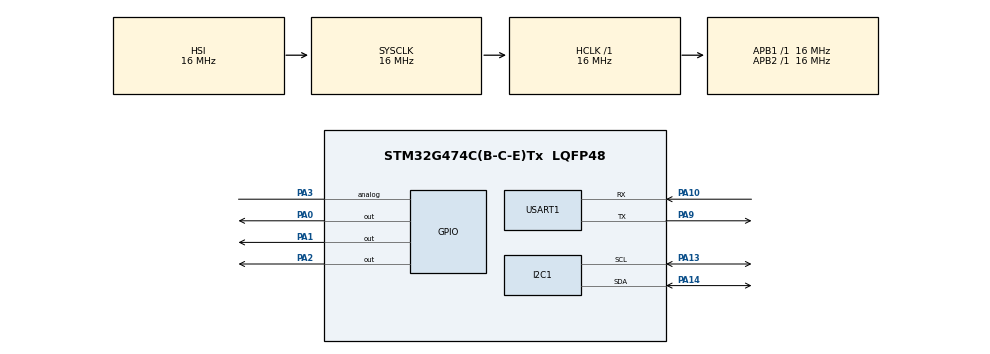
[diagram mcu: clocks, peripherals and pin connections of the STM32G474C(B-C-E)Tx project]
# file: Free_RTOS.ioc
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FREERTOS.BinarySemaphores01=myBinarySem01,Dynamic,NULL,Available
FREERTOS.Tasks01=defaultTask,-2,128,StartDefaultTask,Default,NULL,Dynamic,NULL,NULL;Task3,2,128,Task3_init,Default,NULL,Dynamic,NULL,NULL;Task2,0,128,StartTask03,Default,NULL,Dynamic,NULL,NULL;myTask04,2,128,StartTask04,Default,NULL,Dynamic,NULL,NULL
FREERTOS.configMINIMAL_STACK_SIZE=64
FREERTOS.configUSE_NEWLIB_REENTRANT=1
I2C1.Timing=0x00503D58
Mcu.Family=STM32G4
Mcu.Name=STM32G474C(B-C-E)Tx
Mcu.Package=LQFP48
NVIC.PriorityGroup=NVIC_PRIORITYGROUP_4
NVIC.TIM1_UP_TIM16_IRQn=true\:15\:0\:false\:false\:true\:false\:false\:true\:true
NVIC.TimeBase=TIM1_UP_TIM16_IRQn
NVIC.TimeBaseIP=TIM1
NVIC.USART1_IRQn=true\:5\:0\:false\:false\:true\:true\:true\:true\:true
PA0.Signal=GPIO_Output
PA1.Signal=GPIO_Output
PA10.Mode=Asynchronous
PA10.Signal=USART1_RX
PA13.Mode=I2C
PA13.Signal=I2C1_SCL
PA14.Mode=I2C
PA14.Signal=I2C1_SDA
PA2.Signal=GPIO_Output
PA3.Signal=GPIO_Analog
PA9.Mode=Asynchronous
PA9.Signal=USART1_TX
ProjectManager.HeapSize=0x200
ProjectManager.StackSize=0x400
ProjectManager.TargetToolchain=STM32CubeIDE
RCC.AHBFreq_Value=16000000
RCC.APB1Freq_Value=16000000
RCC.APB1TimFreq_Value=16000000
RCC.APB2Freq_Value=16000000
RCC.APB2TimFreq_Value=16000000
RCC.CortexFreq_Value=16000000
RCC.EXTERNAL_CLOCK_VALUE=12288000
RCC.HCLKFreq_Value=16000000
RCC.HSE_VALUE=8000000
RCC.HSI48_VALUE=48000000
RCC.HSI_VALUE=16000000
RCC.LSE_VALUE=32768
RCC.SYSCLKFreq_VALUE=16000000
RCC.USBFreq_Value=64000000
RCC.VCOOutputFreq_Value=128000000
USART1.VirtualMode-Asynchronous=VM_ASYNC
VP_FREERTOS_VS_CMSIS_V1.Mode=CMSIS_V1
VP_SYS_VS_DBSignals.Mode=DisableDeadBatterySignals
VP_SYS_VS_tim1.Mode=TIM1
board=custom

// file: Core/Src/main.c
/* USER CODE BEGIN Header */
/* USER CODE END Header */
#include "main.h"
#include "cmsis_os.h"

I2C_HandleTypeDef hi2c1;

UART_HandleTypeDef huart1;

osThreadId defaultTaskHandle;
osThreadId Task3Handle;
osThreadId Task2Handle;
osThreadId myTask04Handle;
osSemaphoreId myBinarySem01Handle;

void SystemClock_Config(void);
static void MX_GPIO_Init(void);
static void MX_USART1_UART_Init(void);
static void MX_I2C1_Init(void);
void StartDefaultTask(void const * argument);
void Task3_init(void const * argument);
void StartTask03(void const * argument);
void StartTask04(void const * argument);

int main(void)
{

  /* MCU Configuration--------------------------------------------------------*/

  /* Reset of all peripherals, Initializes the Flash interface and the Systick. */
  HAL_Init();

  /* Configure the system clock */
  SystemClock_Config();

  /* Initialize all configured peripherals */
  MX_GPIO_Init();
  MX_USART1_UART_Init();
  MX_I2C1_Init();

  /* Create the semaphores(s) */
  /* definition and creation of myBinarySem01 */
  osSemaphoreDef(myBinarySem01);
  myBinarySem01Handle = osSemaphoreCreate(osSemaphore(myBinarySem01), 1);

  /* Create the thread(s) */
  /* definition and creation of defaultTask */
  osThreadDef(defaultTask, StartDefaultTask, osPriorityLow, 0, 128);
  defaultTaskHandle = osThreadCreate(osThread(defaultTask), NULL);

  /* definition and creation of Task3 */
  osThreadDef(Task3, Task3_init, osPriorityHigh, 0, 128);
  Task3Handle = osThreadCreate(osThread(Task3), NULL);

  /* definition and creation of Task2 */
  osThreadDef(Task2, StartTask03, osPriorityNormal, 0, 128);
  Task2Handle = osThreadCreate(osThread(Task2), NULL);

  /* definition and creation of myTask04 */
  osThreadDef(myTask04, StartTask04, osPriorityHigh, 0, 128);
  myTask04Handle = osThreadCreate(osThread(myTask04), NULL);

  /* Start scheduler */
  osKernelStart();

  /* We should never get here as control is now taken by the scheduler */

  /* Infinite loop */

}

void SystemClock_Config(void)
{
  RCC_OscInitTypeDef RCC_OscInitStruct = {0};
  RCC_ClkInitTypeDef RCC_ClkInitStruct = {0};

  /** Configure the main internal regulator output voltage
  */
  HAL_PWREx_ControlVoltageScaling(PWR_REGULATOR_VOLTAGE_SCALE1);

  /** Initializes the RCC Oscillators according to the specified parameters
  * in the RCC_OscInitTypeDef structure.
  */
  RCC_OscInitStruct.OscillatorType = RCC_OSCILLATORTYPE_HSI;
  RCC_OscInitStruct.HSIState = RCC_HSI_ON;
  RCC_OscInitStruct.HSICalibrationValue = RCC_HSICALIBRATION_DEFAULT;
  RCC_OscInitStruct.PLL.PLLState = RCC_PLL_NONE;
  if (HAL_RCC_OscConfig(&RCC_OscInitStruct) != HAL_OK)
  {
    Error_Handler();
  }

  /** Initializes the CPU, AHB and APB buses clocks
  */
  RCC_ClkInitStruct.ClockType = RCC_CLOCKTYPE_HCLK|RCC_CLOCKTYPE_SYSCLK
                              |RCC_CLOCKTYPE_PCLK1|RCC_CLOCKTYPE_PCLK2;
  RCC_ClkInitStruct.SYSCLKSource = RCC_SYSCLKSOURCE_HSI;
  RCC_ClkInitStruct.AHBCLKDivider = RCC_SYSCLK_DIV1;
  RCC_ClkInitStruct.APB1CLKDivider = RCC_HCLK_DIV1;
  RCC_ClkInitStruct.APB2CLKDivider = RCC_HCLK_DIV1;

  if (HAL_RCC_ClockConfig(&RCC_ClkInitStruct, FLASH_LATENCY_0) != HAL_OK)
  {
    Error_Handler();
  }
}

static void MX_I2C1_Init(void)
{

  hi2c1.Instance = I2C1;
  hi2c1.Init.Timing = 0x00503D58;
  hi2c1.Init.OwnAddress1 = 0;
  hi2c1.Init.AddressingMode = I2C_ADDRESSINGMODE_7BIT;
  hi2c1.Init.DualAddressMode = I2C_DUALADDRESS_DISABLE;
  hi2c1.Init.OwnAddress2 = 0;
  hi2c1.Init.OwnAddress2Masks = I2C_OA2_NOMASK;
  hi2c1.Init.GeneralCallMode = I2C_GENERALCALL_DISABLE;
  hi2c1.Init.NoStretchMode = I2C_NOSTRETCH_DISABLE;
  if (HAL_I2C_Init(&hi2c1) != HAL_OK)
  {
    Error_Handler();
  }

  /** Configure Analogue filter
  */
  if (HAL_I2CEx_ConfigAnalogFilter(&hi2c1, I2C_ANALOGFILTER_ENABLE) != HAL_OK)
  {
    Error_Handler();
  }

  /** Configure Digital filter
  */
  if (HAL_I2CEx_ConfigDigitalFilter(&hi2c1, 0) != HAL_OK)
  {
    Error_Handler();
  }

}

static void MX_USART1_UART_Init(void)
{

  huart1.Instance = USART1;
  huart1.Init.BaudRate = 115200;
  huart1.Init.WordLength = UART_WORDLENGTH_8B;
  huart1.Init.StopBits = UART_STOPBITS_1;
  huart1.Init.Parity = UART_PARITY_NONE;
  huart1.Init.Mode = UART_MODE_TX_RX;
  huart1.Init.HwFlowCtl = UART_HWCONTROL_NONE;
  huart1.Init.OverSampling = UART_OVERSAMPLING_16;
  huart1.Init.OneBitSampling = UART_ONE_BIT_SAMPLE_DISABLE;
  huart1.Init.ClockPrescaler = UART_PRESCALER_DIV1;
  huart1.AdvancedInit.AdvFeatureInit = UART_ADVFEATURE_NO_INIT;
  if (HAL_UART_Init(&huart1) != HAL_OK)
  {
    Error_Handler();
  }
  if (HAL_UARTEx_SetTxFifoThreshold(&huart1, UART_TXFIFO_THRESHOLD_1_8) != HAL_OK)
  {
    Error_Handler();
  }
  if (HAL_UARTEx_SetRxFifoThreshold(&huart1, UART_RXFIFO_THRESHOLD_1_8) != HAL_OK)
  {
    Error_Handler();
  }
  if (HAL_UARTEx_DisableFifoMode(&huart1) != HAL_OK)
  {
    Error_Handler();
  }

}

static void MX_GPIO_Init(void)
{
  GPIO_InitTypeDef GPIO_InitStruct = {0};

  /* GPIO Ports Clock Enable */
  __HAL_RCC_GPIOA_CLK_ENABLE();

  /*Configure GPIO pin Output Level */
  HAL_GPIO_WritePin(GPIOA, GPIO_PIN_0|GPIO_PIN_1|GPIO_PIN_2, GPIO_PIN_RESET);

  /*Configure GPIO pins : PA0 PA1 PA2 */
  GPIO_InitStruct.Pin = GPIO_PIN_0|GPIO_PIN_1|GPIO_PIN_2;
  GPIO_InitStruct.Mode = GPIO_MODE_OUTPUT_PP;
  GPIO_InitStruct.Pull = GPIO_NOPULL;
  GPIO_InitStruct.Speed = GPIO_SPEED_FREQ_LOW;
  HAL_GPIO_Init(GPIOA, &GPIO_InitStruct);

  /*Configure GPIO pin : PA3 */
  GPIO_InitStruct.Pin = GPIO_PIN_3;
  GPIO_InitStruct.Mode = GPIO_MODE_ANALOG;
  GPIO_InitStruct.Pull = GPIO_NOPULL;
  HAL_GPIO_Init(GPIOA, &GPIO_InitStruct);

}

void StartDefaultTask(void const * argument)
{
}

void Task3_init(void const * argument)
{
  /* USER CODE BEGIN Task3_init */
	for(;;)
	  {
	    // Wait for the semaphore (blocks until it is available)
	    if (osSemaphoreWait(myBinarySem01Handle, osWaitForever) == osOK) {
	      // Critical section: Add the code that should execute when the semaphore is acquired.

	      // Example: Toggle GPIO pin (PA0)
	      HAL_GPIO_TogglePin(GPIOA, GPIO_PIN_0);

	      // No need to release the semaphore here. Task3 simply waits for Task4 to release it.
	    }

	    HAL_Delay(1000); // Delay for 1 second
	  }
  /* USER CODE END Task3_init */
}

void StartTask03(void const * argument)
{
  /* USER CODE BEGIN StartTask03 */
  /* Infinite loop */
	for(;;)
	  {
	    // Task4 will signal Task3 by releasing the semaphore
	    // Example: Toggle GPIO pin (PA1)
	    HAL_GPIO_TogglePin(GPIOA, GPIO_PIN_1);

	    // Release the semaphore
	    osSemaphoreRelease(myBinarySem01Handle);

	    HAL_Delay(2000);  // Delay for 2 seconds
	  }
  /* USER CODE END StartTask03 */
}

void StartTask04(void const * argument)
{
}

void HAL_TIM_PeriodElapsedCallback(TIM_HandleTypeDef *htim)
{
  if (htim->Instance == TIM1) {
    HAL_IncTick();
  }
}

void Error_Handler(void)
{
}
